# MCXC444 register map
Vendor: NXP Semiconductors; Series: MCX; File version: 1.6
CPU: CM0PLUS r0p0, little endian, no MPU, no FPU, VTOR, 2 interrupt priority bits
Registers are 32-bit, read-write, reset 0x0 unless marked. A register's access mark holds for its fields unless they carry their own. Offsets are from the block's base; [hi:lo] are bit positions; {n}, {i} and the like mark numbered series.

## FLEXIO — Flexible I/O - universal I/O module for communication (UART, SPI, I2C, I2S) and PWM purposes.
Base 0x4005F000; register names take the prefix FLEXIO_
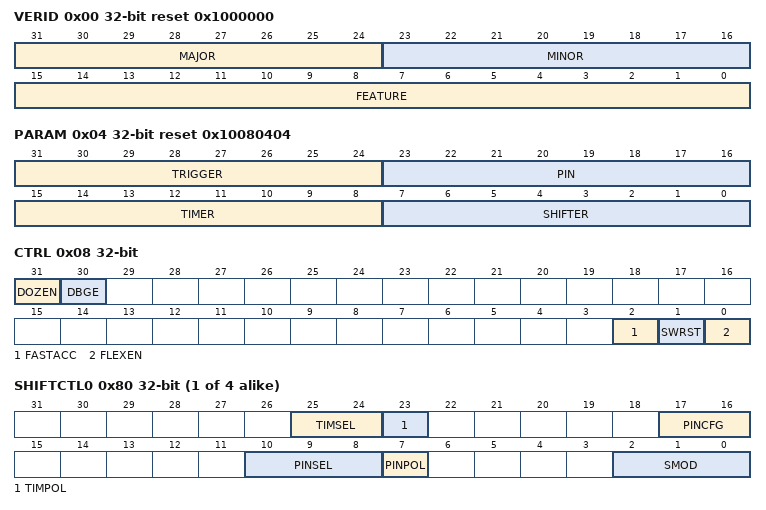
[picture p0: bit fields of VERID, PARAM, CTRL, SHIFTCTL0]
0x00 VERID ro reset 0x1000000 — Version ID Register
  [31:24] MAJOR — Major Version Number
  [23:16] MINOR — Minor Version Number
  [15:0] FEATURE — Feature Specification Number
    0=b0000000000000000 (Standard features implemented.); 1=b0000000000000001 (Supports state, logic and parallel modes.)
0x04 PARAM ro reset 0x10080404 — Parameter Register
  [31:24] TRIGGER — Trigger Number
  [23:16] PIN — Pin Number
  [15:8] TIMER — Timer Number
  [7:0] SHIFTER — Shifter Number
0x08 CTRL — FlexIO Control Register
  [31] DOZEN — Doze Enable
    0=b0 (FlexIO enabled in Doze modes.); 1=b1 (FlexIO disabled in Doze modes.)
  [30] DBGE — Debug Enable
    0=b0 (FlexIO is disabled in debug modes.); 1=b1 (FlexIO is enabled in debug modes)
  [2] FASTACC — Fast Access
    0=b0 (Configures for normal register accesses to FlexIO); 1=b1 (Configures for fast register accesses to FlexIO)
  [1] SWRST — Software Reset
    0=b0 (Software reset is disabled); 1=b1 (Software reset is enabled, all FlexIO registers except the Control Register are reset.)
  [0] FLEXEN — FlexIO Enable
    0=b0 (FlexIO module is disabled.); 1=b1 (FlexIO module is enabled.)
0x10 SHIFTSTAT — Shifter Status Register
  [3:0] SSF — Shifter Status Flag
    0=b0000 (Status flag is clear); 1=b0001 (Status flag is set)
0x14 SHIFTERR — Shifter Error Register
  [3:0] SEF — Shifter Error Flags
    0=b0000 (Shifter Error Flag is clear); 1=b0001 (Shifter Error Flag is set)
0x18 TIMSTAT — Timer Status Register
  [3:0] TSF — Timer Status Flags
    0=b0000 (Timer Status Flag is clear); 1=b0001 (Timer Status Flag is set)
0x20 SHIFTSIEN — Shifter Status Interrupt Enable
  [3:0] SSIE
    0=b0000 (Shifter Status Flag interrupt disabled); 1=b0001 (Shifter Status Flag interrupt enabled)
0x24 SHIFTEIEN — Shifter Error Interrupt Enable
  [3:0] SEIE
    0=b0000 (Shifter Error Flag interrupt disabled); 1=b0001 (Shifter Error Flag interrupt enabled)
0x28 TIMIEN — Timer Interrupt Enable Register
  [3:0] TEIE — Timer Status Interrupt Enable
    0=b0000 (Timer Status Flag interrupt is disabled); 1=b0001 (Timer Status Flag interrupt is enabled)
0x30 SHIFTSDEN — Shifter Status DMA Enable
  [3:0] SSDE
    0=b0000 (Shifter Status Flag DMA request is disabled); 1=b0001 (Shifter Status Flag DMA request is enabled)
{0x80+4i} SHIFTCTL{i} (i=0..3) — Shifter Control N Register
  [25:24] TIMSEL — Timer Select
  [23] TIMPOL — Timer Polarity
    0=b0 (Shift on posedge of Shift clock); 1=b1 (Shift on negedge of Shift clock)
  [17:16] PINCFG — Shifter Pin Configuration
    0=b00 (Shifter pin output disabled); 1=b01 (Shifter pin open drain or bidirectional output enable); 2=b10 (Shifter pin bidirectional output data); 3=b11 (Shifter pin output)
  [10:8] PINSEL — Shifter Pin Select
  [7] PINPOL — Shifter Pin Polarity
    0=b0 (Pin is active high); 1=b1 (Pin is active low)
  [2:0] SMOD — Shifter Mode
    0=b000 (Disabled.); 1=b001 (Receive mode. Captures the current Shifter content into the SHIFTBUF on expiration of the Timer.); 2=b010 (Transmit mode. Load SHIFTBUF contents into the Shifter on expiration of the Timer.); 4=b100 (Match Store mode. Shifter data is compared to SHIFTBUF content on expiration of the Timer.); 5=b101 (Match Continuous mode. Shifter data is continuously compared to SHIFTBUF contents.)
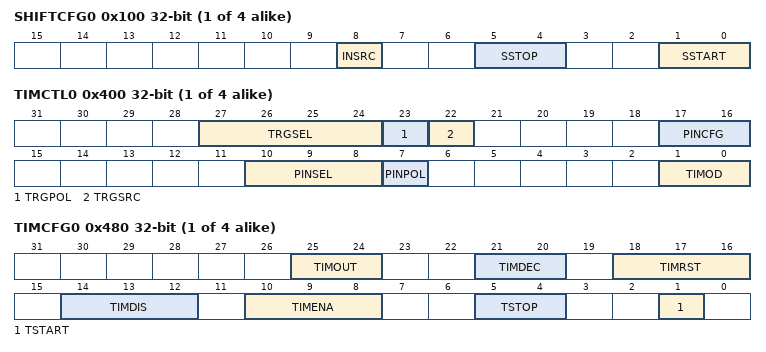
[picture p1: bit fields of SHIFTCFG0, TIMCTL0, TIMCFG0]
{0x100+4i} SHIFTCFG{i} (i=0..3) — Shifter Configuration N Register
  [8] INSRC — Input Source
    0=b0 (Pin); 1=b1 (Shifter N+1 Output)
  [5:4] SSTOP — Shifter Stop bit
    0=b00 (Stop bit disabled for transmitter/receiver/match store); 1=b01 (Reserved for transmitter/receiver/match store); 2=b10 (Transmitter outputs stop bit value 0 on store, receiver/match store sets error flag if stop bit is not 0); 3=b11 (Transmitter outputs stop bit value 1 on store, receiver/match store sets error flag if stop bit is not 1)
  [1:0] SSTART — Shifter Start bit
    0=b00 (Start bit disabled for transmitter/receiver/match store, transmitter loads data on enable); 1=b01 (Start bit disabled for transmitter/receiver/match store, transmitter loads data on first shift); 2=b10 (Transmitter outputs start bit value 0 before loading data on first shift, receiver/match store sets error flag if start bit is not 0); 3=b11 (Transmitter outputs start bit value 1 before loading data on first shift, receiver/match store sets error flag if start bit is not 1)
{0x200+4i} SHIFTBUF{i} (i=0..3) — Shifter Buffer N Register
  [31:0] SHIFTBUF — Shift Buffer
{0x280+4i} SHIFTBUFBIS{i} (i=0..3) — Shifter Buffer N Bit Swapped Register
  [31:0] SHIFTBUFBIS — Shift Buffer
{0x300+4i} SHIFTBUFBYS{i} (i=0..3) — Shifter Buffer N Byte Swapped Register
  [31:0] SHIFTBUFBYS — Shift Buffer
{0x380+4i} SHIFTBUFBBS{i} (i=0..3) — Shifter Buffer N Bit Byte Swapped Register
  [31:0] SHIFTBUFBBS — Shift Buffer
{0x400+4i} TIMCTL{i} (i=0..3) — Timer Control N Register
  [27:24] TRGSEL — Trigger Select
  [23] TRGPOL — Trigger Polarity
    0=b0 (Trigger active high); 1=b1 (Trigger active low)
  [22] TRGSRC — Trigger Source
    0=b0 (External trigger selected); 1=b1 (Internal trigger selected)
  [17:16] PINCFG — Timer Pin Configuration
    0=b00 (Timer pin output disabled); 1=b01 (Timer pin open drain or bidirectional output enable); 2=b10 (Timer pin bidirectional output data); 3=b11 (Timer pin output)
  [10:8] PINSEL — Timer Pin Select
  [7] PINPOL — Timer Pin Polarity
    0=b0 (Pin is active high); 1=b1 (Pin is active low)
  [1:0] TIMOD — Timer Mode
    0=b00 (Timer Disabled.); 1=b01 (Dual 8-bit counters baud/bit mode.); 2=b10 (Dual 8-bit counters PWM mode.); 3=b11 (Single 16-bit counter mode.)
{0x480+4i} TIMCFG{i} (i=0..3) — Timer Configuration N Register
  [25:24] TIMOUT — Timer Output
    0=b00 (Timer output is logic one when enabled and is not affected by timer reset); 1=b01 (Timer output is logic zero when enabled and is not affected by timer reset); 2=b10 (Timer output is logic one when enabled and on timer reset); 3=b11 (Timer output is logic zero when enabled and on timer reset)
  [21:20] TIMDEC — Timer Decrement
    0=b00 (Decrement counter on FlexIO clock, Shift clock equals Timer output.); 1=b01 (Decrement counter on Trigger input (both edges), Shift clock equals Timer output.); 2=b10 (Decrement counter on Pin input (both edges), Shift clock equals Pin input.); 3=b11 (Decrement counter on Trigger input (both edges), Shift clock equals Trigger input.)
  [18:16] TIMRST — Timer Reset
    0=b000 (Timer never reset); 2=b010 (Timer reset on Timer Pin equal to Timer Output); 3=b011 (Timer reset on Timer Trigger equal to Timer Output); 4=b100 (Timer reset on Timer Pin rising edge); 6=b110 (Timer reset on Trigger rising edge); 7=b111 (Timer reset on Trigger rising or falling edge)
  [14:12] TIMDIS — Timer Disable
    0=b000 (Timer never disabled); 1=b001 (Timer disabled on Timer N-1 disable); 2=b010 (Timer disabled on Timer compare); 3=b011 (Timer disabled on Timer compare and Trigger Low); 4=b100 (Timer disabled on Pin rising or falling edge); 5=b101 (Timer disabled on Pin rising or falling edge provided Trigger is high); 6=b110 (Timer disabled on Trigger falling edge)
  [10:8] TIMENA — Timer Enable
    0=b000 (Timer always enabled); 1=b001 (Timer enabled on Timer N-1 enable); 2=b010 (Timer enabled on Trigger high); 3=b011 (Timer enabled on Trigger high and Pin high); 4=b100 (Timer enabled on Pin rising edge); 5=b101 (Timer enabled on Pin rising edge and Trigger high); 6=b110 (Timer enabled on Trigger rising edge); 7=b111 (Timer enabled on Trigger rising or falling edge)
  [5:4] TSTOP — Timer Stop Bit
    0=b00 (Stop bit disabled); 1=b01 (Stop bit is enabled on timer compare); 2=b10 (Stop bit is enabled on timer disable); 3=b11 (Stop bit is enabled on timer compare and timer disable)
  [1] TSTART — Timer Start Bit
    0=b0 (Start bit disabled); 1=b1 (Start bit enabled)
{0x500+4i} TIMCMP{i} (i=0..3) — Timer Compare N Register
  [15:0] CMP — Timer Compare Value
